# nrf51 register map
Vendor: Nordic Semiconductor; Series: nrf51; File version: 522
CPU: CM0 r3p1, little endian, no MPU, no FPU, 2 interrupt priority bits
Registers are 32-bit, read-write, reset 0x0 unless marked. A register's access mark holds for its fields unless they carry their own. Offsets are from the block's base; [hi:lo] are bit positions; {n}, {i} and the like mark numbered series.

## ADC — Analog to digital converter.
Base 0x40007000
0x00 TASKS_START wo — Start an ADC conversion.
0x04 TASKS_STOP wo — Stop ADC.
0x100 EVENTS_END — ADC conversion complete.
0x304 INTENSET — Interrupt enable set register.
  [0] END — Enable interrupt on END event.
    on read: 0=Disabled (Interrupt disabled.); 1=Enabled (Interrupt enabled.) | on write: 1=Set (Enable interrupt on write.)
0x308 INTENCLR — Interrupt enable clear register.
  [0] END — Disable interrupt on END event.
    on read: 0=Disabled (Interrupt disabled.); 1=Enabled (Interrupt enabled.) | on write: 1=Clear (Disable interrupt on write.)
0x400 BUSY ro — ADC busy register.
  [0] BUSY
    0=Ready (No ongoing ADC conversion is taking place. ADC is ready.); 1=Busy (An ADC conversion is taking place. ADC is busy.)
0x500 ENABLE — ADC enable.
  [1:0] ENABLE
    0=Disabled (ADC is disabled.); 1=Enabled (ADC is enabled. If an analog input pin is selected as source of the conversion, the selected pin is configured as an analog input.)
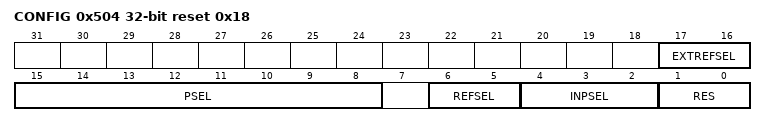
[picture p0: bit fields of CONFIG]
0x504 CONFIG reset 0x18 — ADC configuration register.
  [17:16] EXTREFSEL — ADC external reference pin selection.
    0=None (Analog external reference inputs disabled.); 1=AnalogReference0 (Use analog reference 0 as reference.); 2=AnalogReference1 (Use analog reference 1 as reference.)
  [15:8] PSEL — ADC analog pin selection.
    0=Disabled (Analog input pins disabled.); 1=AnalogInput0 (Use analog input 0 as analog input.); 2=AnalogInput1 (Use analog input 1 as analog input.); 4=AnalogInput2 (Use analog input 2 as analog input.); 8=AnalogInput3 (Use analog input 3 as analog input.); 16=AnalogInput4 (Use analog input 4 as analog input.); 32=AnalogInput5 (Use analog input 5 as analog input.); 64=AnalogInput6 (Use analog input 6 as analog input.); 128=AnalogInput7 (Use analog input 7 as analog input.)
  [6:5] REFSEL — ADC reference selection.
    0=VBG (Use internal 1.2V bandgap voltage as reference for conversion.); 1=External (Use external source configured by EXTREFSEL as reference for conversion.); 2=SupplyOneHalfPrescaling (Use supply voltage with 1/2 prescaling as reference for conversion. Only usable when supply voltage is between 1.7V and 2.6V.); 3=SupplyOneThirdPrescaling (Use supply voltage with 1/3 prescaling as reference for conversion. Only usable when supply voltage is between 2.5V and 3.6V.)
  [4:2] INPSEL — ADC input selection.
    0=AnalogInputNoPrescaling (Analog input specified by PSEL with no prescaling used as input for the conversion.); 1=AnalogInputTwoThirdsPrescaling (Analog input specified by PSEL with 2/3 prescaling used as input for the conversion.); 2=AnalogInputOneThirdPrescaling (Analog input specified by PSEL with 1/3 prescaling used as input for the conversion.); 5=SupplyTwoThirdsPrescaling (Supply voltage with 2/3 prescaling used as input for the conversion.); 6=SupplyOneThirdPrescaling (Supply voltage with 1/3 prescaling used as input for the conversion.)
  [1:0] RES — ADC resolution.
    0=8bit ADC resolution; 1=9bit ADC resolution; 2=10bit ADC resolution
0x508 RESULT ro — Result of ADC conversion.
  [9:0] RESULT
0xFFC POWER — Peripheral power control.
  [0] POWER
    0=Disabled (Module power disabled.); 1=Enabled (Module power enabled.)

## TIMER0
Base 0x40008000
Same registers: TIMER1 0x40009000, TIMER2 0x4000A000
0x00 TASKS_START wo — Start Timer.
0x04 TASKS_STOP wo — Stop Timer.
0x08 TASKS_COUNT wo — Increment Timer (In counter mode).
0x0C TASKS_CLEAR wo — Clear timer.
0x10 TASKS_SHUTDOWN wo — Shutdown timer.
{0x40+4i} TASKS_CAPTURE[{i}] (i=0..3) wo — Capture Timer value to CC[n] registers.
{0x140+4i} EVENTS_COMPARE[{i}] (i=0..3) — Compare event on CC[n] match.
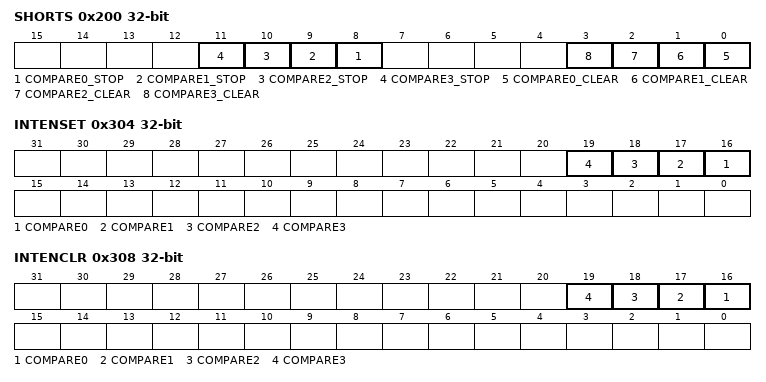
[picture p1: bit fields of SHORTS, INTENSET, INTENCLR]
0x200 SHORTS — Shortcuts for Timer.
  [all] fields
    0=Disabled (Shortcut disabled.); 1=Enabled (Shortcut enabled.)
  [n+8] COMPARE{n}_STOP (n=0..3) — Shortcut between CC[{n}] event and the STOP task.
  [n] COMPARE{n}_CLEAR (n=0..3) — Shortcut between CC[{n}] event and the CLEAR task.
0x304 INTENSET — Interrupt enable set register.
  [all] fields
    on read: 0=Disabled (Interrupt disabled.); 1=Enabled (Interrupt enabled.) | on write: 1=Set (Enable interrupt on write.)
  [n+16] COMPARE{n} (n=0..3) — Enable interrupt on COMPARE[{n}]
0x308 INTENCLR — Interrupt enable clear register.
  [all] fields
    on read: 0=Disabled (Interrupt disabled.); 1=Enabled (Interrupt enabled.) | on write: 1=Clear (Disable interrupt on write.)
  [n+16] COMPARE{n} (n=0..3) — Disable interrupt on COMPARE[{n}]
0x504 MODE — Timer Mode selection.
  [0] MODE — Select Normal or Counter mode.
    1=Counter (Timer in Counter mode.); 0=Timer in Normal mode
0x508 BITMODE — Sets timer behaviour.
  [1:0] BITMODE — Sets timer behaviour ro be like the implementation of a timer with width as indicated.
    0=16-bit timer behaviour; 1=08Bit (8-bit timer behaviour.); 2=24-bit timer behaviour; 3=32-bit timer behaviour
0x510 PRESCALER reset 0x4 — 4-bit prescaler to source clock frequency (max value 9). Source clock frequency is divided by 2^SCALE.
  [3:0] PRESCALER — Timer PRESCALER value. Max value is 9.
{0x540+4i} CC[{i}] (i=0..3) — Capture/compare registers.
0xFFC POWER — Peripheral power control.
  [0] POWER
    0=Disabled (Module power disabled.); 1=Enabled (Module power enabled.)
